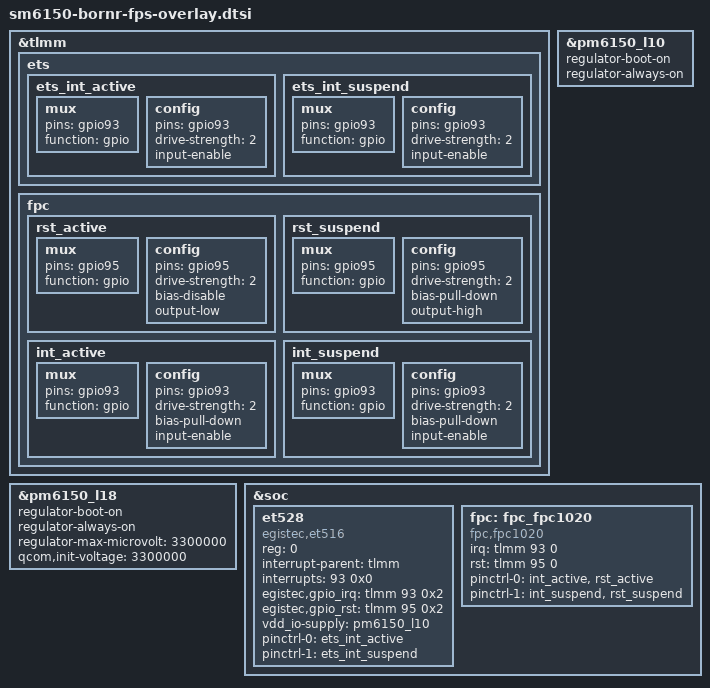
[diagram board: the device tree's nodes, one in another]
&tlmm {
	ets {
		ets_int_active: ets_int_active {
			/* INTERRUPT */
			mux {
				pins = "gpio93";
				function = "gpio";
			};

			config {
				pins = "gpio93";
				drive-strength = <2>; /* 2 MA */
				input-enable;
			};
		};
		ets_int_suspend: ets_int_suspend {
			/* INTERRUPT */
			mux {
				pins = "gpio93";
				function = "gpio";
			};

			config {
				pins = "gpio93";
				drive-strength = <2>; /* 2 MA */
				input-enable;
			};
		};
	};

	fpc {
		rst_active: rst_active {
			/* RESET */
			mux {
				pins = "gpio95";
				function = "gpio";
			};
			config {
				pins = "gpio95";
				drive-strength = <2>; /* 2 MA */
				bias-disable;
				output-low;
			};
		};

		rst_suspend: rst_suspend{
			/* RESET */
			mux {
				pins = "gpio95";
				function = "gpio";
			};

			config {
				pins = "gpio95";
				drive-strength = <2>; /* 2 MA */
				bias-pull-down; /* pull down */
				output-high;
			};
		};

		int_active: int_active {
			/* INTERRUPT */
			mux {
				pins = "gpio93";
				function = "gpio";
			};

			config {
				pins = "gpio93";
				drive-strength = <2>; /* 2 MA */
				bias-pull-down; /* pull down */
				input-enable;
			};
		};

		int_suspend: int_suspend{
			/* INTERRUPT */
			mux {
				pins = "gpio93";
				function = "gpio";
			};

			config {
				pins = "gpio93";
				drive-strength = <2>; /* 2 MA */
				bias-pull-down; /* pull down */
				input-enable;
			};
		};
	};
};

&pm6150_l18 {
	regulator-boot-on;
	regulator-always-on;
	regulator-max-microvolt = <3300000>;
	qcom,init-voltage = <3300000>;
	status = "ok";
};

&pm6150_l10 {
	regulator-boot-on;
	regulator-always-on;
	status = "ok";
};

&soc {
	et528: et528 {
		compatible = "egistec,et516";
		status = "ok";
		reg = <0>;
		interrupt-parent = <&tlmm>;
		interrupts = <93 0x0>;
		egistec,gpio_irq = <&tlmm 93 0x2>;
		egistec,gpio_rst = <&tlmm 95 0x2>;
		vdd_io-supply = <&pm6150_l10>;

		pinctrl-names = "default", "suspend";
		pinctrl-0 = <&ets_int_active>;
		pinctrl-1 = <&ets_int_suspend>;
	};

	fpc: fpc_fpc1020 {
		compatible = "fpc,fpc1020";
		status = "ok";
		irq = <&tlmm 93 0>;
		rst = <&tlmm 95 0>;
		pinctrl-names = "default", "suspend";
		pinctrl-0 = <&int_active &rst_active>;
		pinctrl-1 = <&int_suspend &rst_suspend>;
	};
};
